VERSION ""

NS_ :

BS_:

BU_: ECU1

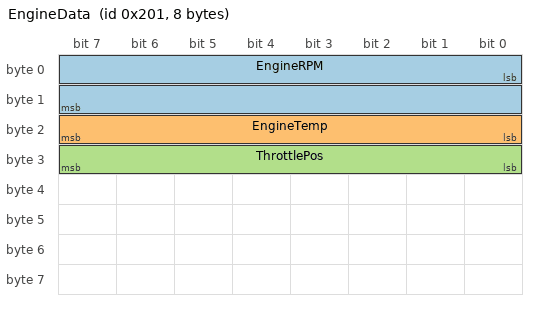
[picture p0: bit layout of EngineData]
BO_ 513 EngineData: 8 ECU1
 SG_ EngineRPM : 0|16@1+ (0.1,0) [0|8000] "rpm" Vector__XXX
 SG_ EngineTemp : 16|8@1+ (1,-40) [-40|215] "degC" Vector__XXX
 SG_ ThrottlePos : 24|8@1+ (0.4,0) [0|100] "%" Vector__XXX

BO_ 514 VehicleSpeed: 4 ECU1
 SG_ Speed : 0|16@1+ (0.01,0) [0|300] "km/h" Vector__XXX
 SG_ GearPos : 16|4@1+ (1,0) [0|8] "" Vector__XXX
